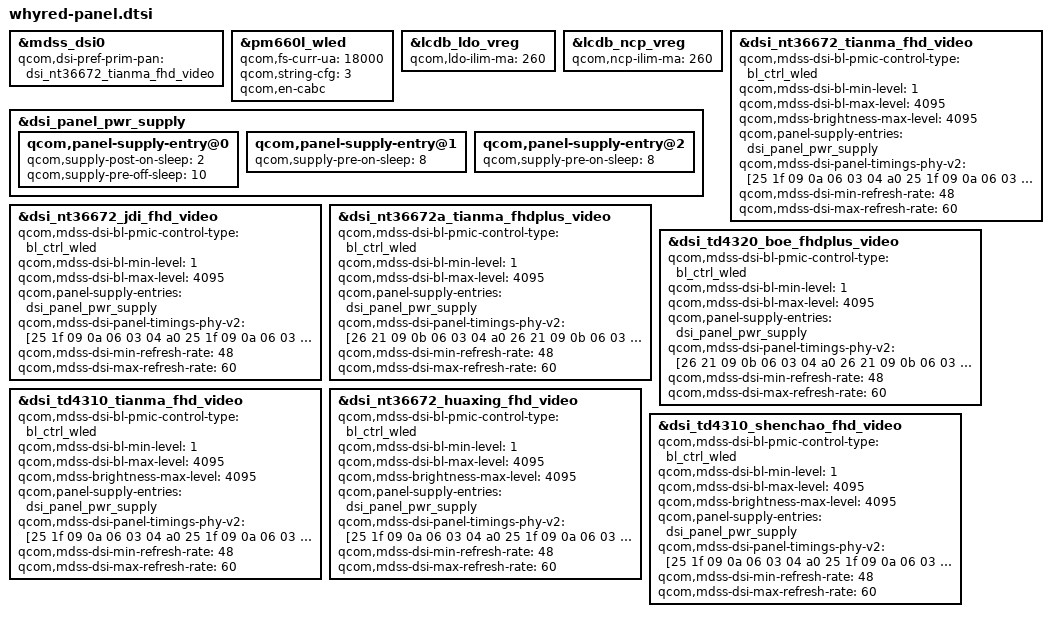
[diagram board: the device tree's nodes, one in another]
/* Copyright (c) 2017, The Linux Foundation. All rights reserved.
 * Copyright (C) 2019 XiaoMi, Inc.
 *
 * This program is free software; you can redistribute it and/or modify
 * it under the terms of the GNU General Public License version 2 and
 * only version 2 as published by the Free Software Foundation.
 *
 * This program is distributed in the hope that it will be useful,
 * but WITHOUT ANY WARRANTY; without even the implied warranty of
 * MERCHANTABILITY or FITNESS FOR A PARTICULAR PURPOSE.  See the
 * GNU General Public License for more details.
*/

#include "panel/dsi-panel-tianma-nt36672-1080p-video.dtsi"
#include "panel/dsi-panel-jdi-nt36672-1080p-video.dtsi"
#include "panel/dsi-panel-tianma-nt36672a-1080p-video.dtsi"
#include "panel/dsi-panel-boe-td4320-1080p-video.dtsi"
#include "panel/dsi-panel-tianma-td4310-1080p-video.dtsi"
#include "panel/dsi-panel-huaxing-nt36672-1080p-video.dtsi"
#include "panel/dsi-panel-shenchao-td4310-1080p-video.dtsi"

&mdss_dsi0 {
	qcom,dsi-pref-prim-pan = <&dsi_nt36672_tianma_fhd_video>;
};

&pm660l_wled {
	qcom,fs-curr-ua = <18000>;
	qcom,string-cfg = <3>;
	qcom,en-cabc;
	/delete-property/ qcom,auto-calibration-enable;
};

&lcdb_ldo_vreg {
	qcom,ldo-ilim-ma = <260>;
};

&lcdb_ncp_vreg {
	qcom,ncp-ilim-ma = <260>;
};

&dsi_panel_pwr_supply {
	qcom,panel-supply-entry@0 {
		qcom,supply-post-on-sleep = <2>;
		qcom,supply-pre-off-sleep = <10>;
	};

	qcom,panel-supply-entry@1 {
		qcom,supply-pre-on-sleep = <8>;
	};

	qcom,panel-supply-entry@2 {
		qcom,supply-pre-on-sleep = <8>;
	};
};

&dsi_nt36672_tianma_fhd_video {
	qcom,mdss-dsi-bl-pmic-control-type = "bl_ctrl_wled";
	qcom,mdss-dsi-bl-min-level = <1>;
	qcom,mdss-dsi-bl-max-level = <4095>;
	qcom,mdss-brightness-max-level = <4095>;
	qcom,panel-supply-entries = <&dsi_panel_pwr_supply>;
	qcom,mdss-dsi-panel-timings-phy-v2 = [25 1f 09 0a 06 03 04 a0
		25 1f 09 0a 06 03 04 a0
		25 1f 09 0a 06 03 04 a0
		25 1f 09 0a 06 03 04 a0
		25 1e 08 0a 06 03 04 a0];
	qcom,mdss-dsi-min-refresh-rate = <48>;
	qcom,mdss-dsi-max-refresh-rate = <60>;
};

&dsi_nt36672_jdi_fhd_video {
	qcom,mdss-dsi-bl-pmic-control-type = "bl_ctrl_wled";
	qcom,mdss-dsi-bl-min-level = <1>;
	qcom,mdss-dsi-bl-max-level = <4095>;
	qcom,panel-supply-entries = <&dsi_panel_pwr_supply>;
	qcom,mdss-dsi-panel-timings-phy-v2 = [25 1f 09 0a 06 03 04 a0
		25 1f 09 0a 06 03 04 a0
		25 1f 09 0a 06 03 04 a0
		25 1f 09 0a 06 03 04 a0
		25 1e 08 0a 06 03 04 a0];
	qcom,mdss-dsi-min-refresh-rate = <48>;
	qcom,mdss-dsi-max-refresh-rate = <60>;
};

&dsi_nt36672a_tianma_fhdplus_video {
	qcom,mdss-dsi-bl-pmic-control-type = "bl_ctrl_wled";
	qcom,mdss-dsi-bl-min-level = <1>;
	qcom,mdss-dsi-bl-max-level = <4095>;
	qcom,panel-supply-entries = <&dsi_panel_pwr_supply>;
	qcom,mdss-dsi-panel-timings-phy-v2 = [26 21 09 0b 06 03 04 a0
		26 21 09 0b 06 03 04 a0
		26 21 09 0b 06 03 04 a0
		26 21 09 0b 06 03 04 a0
		26 20 0a 0b 06 03 04 a0];
	qcom,mdss-dsi-min-refresh-rate = <48>;
	qcom,mdss-dsi-max-refresh-rate = <60>;
};

&dsi_td4320_boe_fhdplus_video {
	qcom,mdss-dsi-bl-pmic-control-type = "bl_ctrl_wled";
	qcom,mdss-dsi-bl-min-level = <1>;
	qcom,mdss-dsi-bl-max-level = <4095>;
	qcom,panel-supply-entries = <&dsi_panel_pwr_supply>;
	qcom,mdss-dsi-panel-timings-phy-v2 = [26 21 09 0b 06 03 04 a0
		26 21 09 0b 06 03 04 a0
		26 21 09 0b 06 03 04 a0
		26 21 09 0b 06 03 04 a0
		26 20 0a 0b 06 03 04 a0];
	qcom,mdss-dsi-min-refresh-rate = <48>;
	qcom,mdss-dsi-max-refresh-rate = <60>;
};

&dsi_td4310_tianma_fhd_video {
	qcom,mdss-dsi-bl-pmic-control-type = "bl_ctrl_wled";
	qcom,mdss-dsi-bl-min-level = <1>;
	qcom,mdss-dsi-bl-max-level = <4095>;
	qcom,mdss-brightness-max-level = <4095>;
	qcom,panel-supply-entries = <&dsi_panel_pwr_supply>;
	qcom,mdss-dsi-panel-timings-phy-v2 = [25 1f 09 0a 06 03 04 a0
		25 1f 09 0a 06 03 04 a0
		25 1f 09 0a 06 03 04 a0
		25 1f 09 0a 06 03 04 a0
		25 1f 08 0a 06 03 04 a0];
	qcom,mdss-dsi-min-refresh-rate = <48>;
	qcom,mdss-dsi-max-refresh-rate = <60>;
};

&dsi_nt36672_huaxing_fhd_video {
	qcom,mdss-dsi-bl-pmic-control-type = "bl_ctrl_wled";
	qcom,mdss-dsi-bl-min-level = <1>;
	qcom,mdss-dsi-bl-max-level = <4095>;
	qcom,mdss-brightness-max-level = <4095>;
	qcom,panel-supply-entries = <&dsi_panel_pwr_supply>;
	qcom,mdss-dsi-panel-timings-phy-v2 = [25 1f 09 0a 06 03 04 a0
		25 1f 09 0a 06 03 04 a0
		25 1f 09 0a 06 03 04 a0
		25 1f 09 0a 06 03 04 a0
		25 1e 08 0a 06 03 04 a0];
	qcom,mdss-dsi-min-refresh-rate = <48>;
	qcom,mdss-dsi-max-refresh-rate = <60>;
};

&dsi_td4310_shenchao_fhd_video {
	qcom,mdss-dsi-bl-pmic-control-type = "bl_ctrl_wled";
	qcom,mdss-dsi-bl-min-level = <1>;
	qcom,mdss-dsi-bl-max-level = <4095>;
	qcom,mdss-brightness-max-level = <4095>;
	qcom,panel-supply-entries = <&dsi_panel_pwr_supply>;
	qcom,mdss-dsi-panel-timings-phy-v2 = [25 1f 09 0a 06 03 04 a0
		25 1f 09 0a 06 03 04 a0
		25 1f 09 0a 06 03 04 a0
		25 1f 09 0a 06 03 04 a0
		25 1e 08 0a 06 03 04 a0];
	qcom,mdss-dsi-min-refresh-rate = <48>;
	qcom,mdss-dsi-max-refresh-rate = <60>;
};
